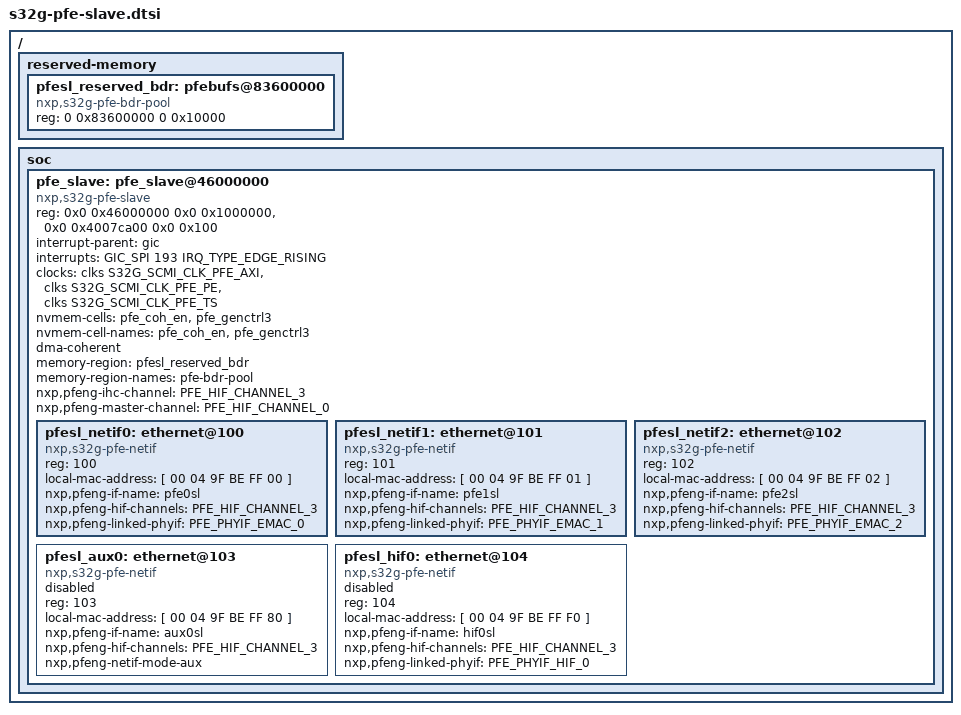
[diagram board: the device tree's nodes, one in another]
// SPDX-License-Identifier: GPL-2.0
/*
 * Copyright 2022-2023 NXP
 *
 * Net devices mapping:
 *   pfe0sl: to EMAC_0
 *   pfe1sl: to EMAC_1
 *   pfe2sl: to EMAC_2
 *   aux0sl: to CLASS
 *   hif0sl: to HIF_0
 */

#include <dt-bindings/clock/s32g-scmi-clock.h>
#include <dt-bindings/net/s32g-pfe.h>

/ {
	reserved-memory {
		 pfesl_reserved_bdr: pfebufs@83600000 {
			compatible = "nxp,s32g-pfe-bdr-pool";
			/* 64 KB */
			reg = <0 0x83600000 0 0x10000>;
			status = "okay";
		};
		/* ends 0x83610000 */
	};

	soc {
		pfe_slave: pfe_slave@46000000 {
			compatible = "nxp,s32g-pfe-slave";
			reg = <0x0 0x46000000 0x0 0x1000000>,
			      <0x0 0x4007ca00 0x0 0x100>;
			reg-names = "pfe-cbus", "s32g-main-gpr";
			#address-cells = <1>;
			#size-cells = <0>;
			interrupt-parent = <&gic>;
			interrupts = <GIC_SPI 193 IRQ_TYPE_EDGE_RISING>;
			interrupt-names = "hif3";
			clocks = <&clks S32G_SCMI_CLK_PFE_AXI>,
				 <&clks S32G_SCMI_CLK_PFE_PE>,
				 <&clks S32G_SCMI_CLK_PFE_TS>;
			clock-names = "pfe_sys", "pfe_pe", "pfe_ts";
			nvmem-cells = <&pfe_coh_en>, <&pfe_genctrl3>;
			nvmem-cell-names = "pfe_coh_en", "pfe_genctrl3";
			dma-coherent;
			memory-region = <&pfesl_reserved_bdr>;
			memory-region-names = "pfe-bdr-pool";
			nxp,pfeng-ihc-channel = <PFE_HIF_CHANNEL_3>;
			nxp,pfeng-master-channel = <PFE_HIF_CHANNEL_0>;
			status = "okay";

			/* Network interface 'pfe0sl' */
			pfesl_netif0: ethernet@100 {
				compatible = "nxp,s32g-pfe-netif";
				status = "okay";
				reg = <100>;
				local-mac-address = [ 00 04 9F BE FF 00 ];
				nxp,pfeng-if-name = "pfe0sl";
				nxp,pfeng-hif-channels = <PFE_HIF_CHANNEL_3>;
				nxp,pfeng-linked-phyif = <PFE_PHYIF_EMAC_0>;
			};

			/* Network interface 'pfe1sl' */
			pfesl_netif1: ethernet@101 {
				compatible = "nxp,s32g-pfe-netif";
				status = "okay";
				reg = <101>;
				local-mac-address = [ 00 04 9F BE FF 01 ];
				nxp,pfeng-if-name = "pfe1sl";
				nxp,pfeng-hif-channels = <PFE_HIF_CHANNEL_3>;
				nxp,pfeng-linked-phyif = <PFE_PHYIF_EMAC_1>;
			};

			/* Network interface 'pfe2sl' */
			pfesl_netif2: ethernet@102 {
				compatible = "nxp,s32g-pfe-netif";
				status = "okay";
				reg = <102>;
				local-mac-address = [ 00 04 9F BE FF 02 ];
				nxp,pfeng-if-name = "pfe2sl";
				nxp,pfeng-hif-channels = <PFE_HIF_CHANNEL_3>;
				nxp,pfeng-linked-phyif = <PFE_PHYIF_EMAC_2>;
			};

			/* Network interface 'aux0sl' */
			pfesl_aux0: ethernet@103 {
				compatible = "nxp,s32g-pfe-netif";
				status = "disabled";
				reg = <103>;
				local-mac-address = [ 00 04 9F BE FF 80 ];
				nxp,pfeng-if-name = "aux0sl";
				nxp,pfeng-hif-channels = <PFE_HIF_CHANNEL_3>;
				nxp,pfeng-netif-mode-aux;
			};

			/* Network interface 'hif0sl' */
			pfesl_hif0: ethernet@104 {
				compatible = "nxp,s32g-pfe-netif";
				status = "disabled";
				reg = <104>;
				local-mac-address = [ 00 04 9F BE FF F0 ];
				nxp,pfeng-if-name = "hif0sl";
				nxp,pfeng-hif-channels = <PFE_HIF_CHANNEL_3>;
				nxp,pfeng-linked-phyif = <PFE_PHYIF_HIF_0>;
			};
		};
	};
};

